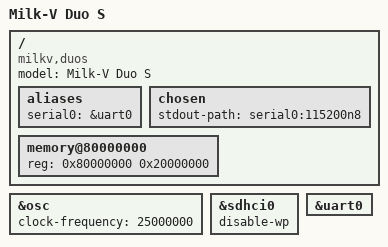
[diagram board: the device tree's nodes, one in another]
// SPDX-License-Identifier: (GPL-2.0 OR MIT)
/*
 * Copyright (C) 2024 Michael Opdenacker <michael.opdenacker@bootlin.com>
 */

/dts-v1/;

#include "cv1800b.dtsi"

/ {
	model = "Milk-V Duo S";
	compatible = "milkv,duos", "sophgo,cv1800b";

	aliases {
		serial0 = &uart0;
	};

	chosen {
		stdout-path = "serial0:115200n8";
	};

	memory@80000000 {
		device_type = "memory";
		reg = <0x80000000 0x20000000>;
	};
};

&osc {
	clock-frequency = <25000000>;
};

&sdhci0 {
	status = "okay";
	disable-wp;
};

&uart0 {
	status = "okay";
};
